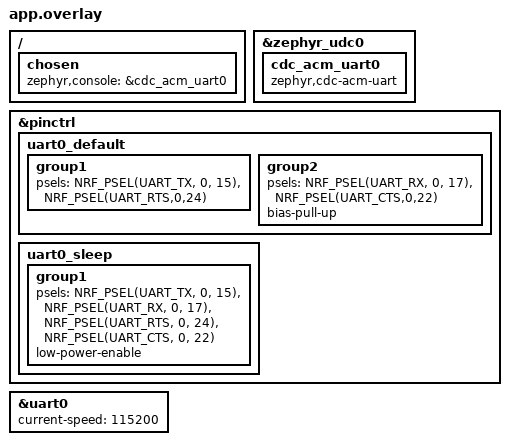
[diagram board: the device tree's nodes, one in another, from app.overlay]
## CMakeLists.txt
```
# SPDX-License-Identifier: Apache-2.0

cmake_minimum_required(VERSION 3.20.0)

find_package(Zephyr REQUIRED HINTS $ENV{ZEPHYR_BASE})
project(nRF52840_Pololu)

FILE(GLOB app_sources src/*.c)
target_sources(app PRIVATE ${app_sources})
```

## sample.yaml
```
sample:
  description: nRF52840 project for mimicing nRF52840 as an crazyflie
  name: nRF52840_Pololu
```

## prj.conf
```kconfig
CONFIG_CONSOLE=y
CONFIG_LOG=y
CONFIG_STDOUT_CONSOLE=y

# Use UART for Console
CONFIG_SERIAL=y
# CONFIG_UART_CONSOLE=y

# Use Segger RTT Console
#CONFIG_RTT_CONSOLE=y
#CONFIG_USE_SEGGER_RTT=y

# USB CDC Console Options:
# If using USB-CDC ensure app.overlay is present
CONFIG_USB_DEVICE_STACK=y
CONFIG_USB_DEVICE_PRODUCT="Zephyr Console"
CONFIG_UART_LINE_CTRL=y
CONFIG_USB_CDC_ACM=y
# Values below are for testing and MUST be configured for USB products
CONFIG_USB_DEVICE_VID=0x2FE3
CONFIG_USB_DEVICE_PID=0x100

CONFIG_NCS_SAMPLES_DEFAULTS=y
CONFIG_ESB=y

CONFIG_SYS_CLOCK_TICKS_PER_SEC=1000

CONFIG_CBPRINTF_FP_SUPPORT=y
```

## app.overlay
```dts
/*
 * Copyright (c) 2021 Nordic Semiconductor ASA
 *
 * SPDX-License-Identifier: Apache-2.0
 */


/ {
    chosen {
        zephyr,console = &cdc_acm_uart0;
    };
};

&zephyr_udc0 {
    cdc_acm_uart0: cdc_acm_uart0 {
        compatible = "zephyr,cdc-acm-uart";
    };
};

&pinctrl {
    uart0_default: uart0_default {
        group1 {
            psels = <NRF_PSEL(UART_TX, 0, 15)>,
                    <NRF_PSEL(UART_RTS,0,24)>;
        };
        group2 {
            psels = <NRF_PSEL(UART_RX, 0, 17)>,
                    <NRF_PSEL(UART_CTS,0,22)>;
            bias-pull-up;
        };
    };

	uart0_sleep: uart0_sleep {
		group1 {
			psels = <NRF_PSEL(UART_TX, 0, 15)>,
				<NRF_PSEL(UART_RX, 0, 17)>,
				<NRF_PSEL(UART_RTS, 0, 24)>,
				<NRF_PSEL(UART_CTS, 0, 22)>;
			low-power-enable;
		};
	};
};

&uart0 {
    current-speed = <115200>;
};
```

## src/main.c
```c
/*
 * Async ESB PRX with CRTP Handshake + Log Timer + param TOC/read/write
 * Author: Jiaming Li/Charlotte Stentzler
 * (Zephyr + nRF52840, Async Queue Version)
 */

#include <zephyr/device.h>
#include <zephyr/devicetree.h>
#include <zephyr/drivers/clock_control.h>
#include <zephyr/drivers/clock_control/nrf_clock_control.h>
#include <zephyr/drivers/gpio.h>
#include <zephyr/logging/log.h>
#include <zephyr/kernel.h>
#include <zephyr/types.h>
#include <nrf.h>
#include <esb.h>

#include "uart.h"
#include "led.h"
#include "robot_state.h"
#include "crtp.h"
#include "nrf_esb.h"
#include "crtp_param.h"
#include "crtp_log.h"


LOG_MODULE_REGISTER(esb_prx, CONFIG_ESB_PRX_APP_LOG_LEVEL);


K_THREAD_DEFINE(rx_thread_id, 2048, rx_worker, NULL, NULL, NULL, 3, 0, 0);

K_THREAD_DEFINE(tx_thread_id, 1024, tx_worker, NULL, NULL, NULL, 5, 0, 0);

K_THREAD_DEFINE(log_thread_id, 1024, log_task, NULL, NULL, NULL, 6, 0, 0);

K_THREAD_DEFINE(decode_thread_id, 1024, decode_worker, NULL, NULL, NULL, 7, 0, 0);

/* ============================ SYSTEM INIT ============================ */
int clocks_start(void)
{
    int err, res;
    struct onoff_manager *mgr;
    struct onoff_client cli;
    mgr = z_nrf_clock_control_get_onoff(CLOCK_CONTROL_NRF_SUBSYS_HF);
    if (!mgr) return -ENXIO;
    sys_notify_init_spinwait(&cli.notify);
    err = onoff_request(mgr, &cli);
    do { err = sys_notify_fetch_result(&cli.notify, &res); } while (err);
    return 0;
}

/* ============================ MAIN ============================ */
int main(void)
{
    /* BOOT MARKER - should appear immediately */
    LOG_INF("========================================");
    LOG_INF("=== nRF52840_Pololu Firmware v1.0 ===");
    LOG_INF("========================================");
    
    LOG_INF("Async ESB PRX Start");
    clocks_start();
    esb_initialize();
    esb_start_rx();
    log_blocks_init();
    uart_initialization();
    leds_init();

    LOG_INF("Ready for Crazyflie handshake + log streaming + param read/write");
    LOG_INF("========================================");
    LOG_INF("Missing components: robot status handling");
    LOG_INF("running basic tests ...");

    // Test: Send a parameter to robot on startup to verify UART TX
    k_msleep(1000);
    send_test_param_to_robot();

    uint32_t last_heartbeat = 0;
    uint32_t last_log_print = 0;
    uint32_t rx_count = 0;
    bool param_sync_reported = false;

    struct esb_payload cmd;
    while (1) {
        if (uart_queue_receive(&cmd) == 0) {
            rx_count++;
            if (is_parameter_packet(cmd.data, cmd.length)) {
                handle_parameter_packet(cmd.data, cmd.length);
                LOG_INF(">>> Param updated from ROBOT <<<");
                print_all_parameters();
            } else {
                // Forward other packets to radio
                esb_send_async(&cmd);
            }
        }

        uint32_t now = k_uptime_get_32();

        // Print log table every 30s
        if (now - last_log_print > 30000) {
            print_log_table();
            last_log_print = now;
        }

        // Heartbeat every 5s with RX counter
        if (now - last_heartbeat > 5000) {
            LOG_INF("Heartbeat: RX=%d uptime=%ds", rx_count, now/1000);
            last_heartbeat = now;

            // Check param sync status periodically until complete
            if (!param_sync_reported) {
                if (check_param_sync_status()) {
                    param_sync_reported = true;
                }
            }
        }

        k_msleep(50);
    }
}
```

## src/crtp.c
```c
#include "crtp.h"

/* Use the logging module registered in main.c */
LOG_MODULE_DECLARE(esb_prx);

uint8_t my_downlink_ctr = 0;

/* ============================ CRTP HANDLERS ============================ */
/* SCAN */
bool handle_scan_packet(const uint8_t *data, uint8_t len, uint8_t pipe)
{
    if (len == 3 && data[0] == 0xFF && data[1] == 0x05 && data[2] == 0x01)
    {
        struct esb_payload tx = {0};
        tx.pipe = pipe;
        tx.length = 3;
        memcpy(tx.data, data, 3);
        esb_send_async(&tx);
        LOG_INF("SCAN packet reply");
        return true;
    }
    return false;
}

/* KEEPALIVE */
bool handle_keepalive(const uint8_t *data, uint8_t len, uint8_t pipe)
{
    if (len == 1 && (data[0] & 0xF3) == 0xF3)
    {
        struct esb_payload tx = {0};
        tx.pipe = pipe;
        tx.length = 2;
        tx.data[0] = (0xAA & 0xF3) | (data[0] & 0x08) | (my_downlink_ctr << 2);
        tx.data[1] = 0x55;
        esb_send_async(&tx);
        my_downlink_ctr ^= 1;
        return true;
    }
    return false;
}

/* ========================== TX WORKER ========================== */
void tx_worker(void)
{
    struct esb_payload tx;

    while (1)
    {
        if (k_msgq_get(&tx_queue, &tx, K_FOREVER) == 0)
        {
            int ret;
            do
            {
                ret = esb_write_payload(&tx);
                if (ret != 0)
                {
                    k_msleep(1);
                }
            } while (ret != 0);
        }
    }
}

/* ========================== RX THREAD ========================== */
void rx_worker(void)
{
    struct esb_payload rx;
    while (1)
    {
        if (k_msgq_get(&rx_queue, &rx, K_FOREVER) == 0)
        {
            handle_received_packet(&rx);
        }
    }
}

void handle_received_packet(struct esb_payload *rx)
{
    uint8_t *data = rx->data;
    uint8_t len = rx->length;
    uint8_t pipe = rx->pipe;

    if (handle_scan_packet(data, len, pipe))
        return;
    if (handle_keepalive(data, len, pipe))
        return;

    uint8_t hdr = data[0] & 0xF3;
    uint8_t chan = (hdr & 0x0F);
    uint8_t port = ((hdr >> 4) & 0x0F);
    const uint8_t *pl = &data[1];
    uint8_t plen = len - 1;

    bool handled = false;

    handled |= handle_platform_crtp(port, chan, pl, plen, hdr, pipe);
    handled |= handle_param_crtp(port, chan, pl, plen, hdr, pipe);
    handled |= handle_memory_crtp(port, chan, pl, plen, hdr, pipe);
    handled |= handle_log_crtp(port, chan, pl, plen, hdr, pipe);

    if (!handled)
    {
        print_uart_payload(rx->data, rx->length);
        // LOG_INF("Forward non-CRTP packet to UART, len=%d %d %d", rx->data[0], rx->data[1], rx->data[2]);
    }
}
```

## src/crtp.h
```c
#pragma once
#ifndef CRTP_H
#define CRTP_H

#include <zephyr/device.h>
#include <zephyr/devicetree.h>
#include <zephyr/drivers/clock_control.h>
#include <zephyr/drivers/clock_control/nrf_clock_control.h>
#include <zephyr/drivers/gpio.h>
#include <zephyr/logging/log.h>
#include <zephyr/kernel.h>
#include <zephyr/types.h>
#include <nrf.h>
#include <esb.h>

#include "uart.h"
#include "robot_state.h"
#include "crtp_log.h"
#include "crtp_param.h"
#include "crtp_memory.h"
#include "crtp_platform.h"

extern uint8_t my_downlink_ctr;

/* Note: do NOT declare the log module in headers — declare per .c file */

extern struct k_msgq tx_queue;
extern struct k_msgq rx_queue;

/* ============================ CRTP HANDLERS ============================ */
bool handle_scan_packet(const uint8_t *data, uint8_t len, uint8_t pipe);
bool handle_keepalive(const uint8_t *data, uint8_t len, uint8_t pipe);

void tx_worker(void);
void rx_worker(void);
void handle_received_packet(struct esb_payload *rx);

#endif
```

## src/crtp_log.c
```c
#include "crtp_log.h"

/* Use the logging module registered in main.c */
LOG_MODULE_DECLARE(esb_prx);

/* Define the log blocks storage (single definition for the extern in header) */
log_block_t log_blocks[LOG_BLOCK_ID_MAX];

/* Access the new robot_log state */
extern log_snapshot_t robot_log;
extern struct k_mutex robot_log_lock;

/* ========================== LOG BLOCK HANDLING ========================== */
void log_blocks_init(void)
{
    for (int i = 0; i < LOG_BLOCK_ID_MAX; i++) {
        log_blocks[i].active = false;
        log_blocks[i].block_id = i;
        log_blocks[i].period_ms = 0;
        memset(log_blocks[i].vars, 0, sizeof(log_blocks[i].vars));
    }
}

/* ========================== LOG THREAD ========================== */
void log_task(void)
{
    uint32_t last_sent[LOG_BLOCK_ID_MAX] = {0};

    while (1) {
        uint32_t now = k_uptime_get_32();

        for (int i = 0; i < LOG_BLOCK_ID_MAX; i++) {
            if (!log_blocks[i].active)
                continue;

            if (now - last_sent[i] < (log_blocks[i].period_ms * 10))
                continue;

            last_sent[i] = now;

            // Read current log snapshot under mutex
            log_snapshot_t log;
            k_mutex_lock(&robot_log_lock, K_FOREVER);
            log = robot_log;
            k_mutex_unlock(&robot_log_lock);

            uint32_t ts = now & 0xFFFFFF;

            struct esb_payload tx = {0};
            tx.pipe = 0;
            tx.length = 1 + 3 + 1 + 6 * sizeof(float);
            tx.data[0] = (5 << 4) | 2 | (my_downlink_ctr << 2);
            tx.data[1] = log_blocks[i].block_id;
            memcpy(&tx.data[2], &ts, 3);

            if (log_blocks[i].block_id == 0) {
                // Block 0: position + velocity (x, y, yaw, x_des, y_des, yaw_des)
                memcpy(&tx.data[5], &log.x, 4);
                memcpy(&tx.data[9], &log.y, 4);
                memcpy(&tx.data[13], &log.yaw, 4);
                memcpy(&tx.data[17], &log.x_des, 4);
                memcpy(&tx.data[21], &log.y_des, 4);
                memcpy(&tx.data[25], &log.yaw_des, 4);
            }
            else if (log_blocks[i].block_id == 1) {
                // Block 1: errors + feedforward (x_err, y_err, yaw_err, v_ff, w_ff, 0)
                float zero = 0.0f;
                memcpy(&tx.data[5], &log.x_err, 4);
                memcpy(&tx.data[9], &log.y_err, 4);
                memcpy(&tx.data[13], &log.yaw_err, 4);
                memcpy(&tx.data[17], &log.v_ff, 4);
                memcpy(&tx.data[21], &log.w_ff, 4);
                memcpy(&tx.data[25], &zero, 4);
            }
            else if (log_blocks[i].block_id == 2) {
                // Block 2: wheel data (duty_l, duty_r, omega_l_cmd, omega_r_cmd, omega_l_meas, omega_r_meas)
                memcpy(&tx.data[5], &log.duty_l, 4);
                memcpy(&tx.data[9], &log.duty_r, 4);
                memcpy(&tx.data[13], &log.omega_l_cmd, 4);
                memcpy(&tx.data[17], &log.omega_r_cmd, 4);
                memcpy(&tx.data[21], &log.omega_l_meas, 4);
                memcpy(&tx.data[25], &log.omega_r_meas, 4);
            }
            else if (log_blocks[i].block_id == 3) {
                // Block 3: status (robot_mode, robot_running, t_ms as float, 0, 0, 0)
                extern uint8_t robot_mode;
                extern uint8_t robot_running;
                float mode_f = (float)robot_mode;
                float running_f = (float)robot_running;
                float t_ms_f = (float)log.t_ms;
                float zero = 0.0f;
                memcpy(&tx.data[5], &mode_f, 4);
                memcpy(&tx.data[9], &running_f, 4);
                memcpy(&tx.data[13], &t_ms_f, 4);
                memcpy(&tx.data[17], &zero, 4);
                memcpy(&tx.data[21], &zero, 4);
                memcpy(&tx.data[25], &zero, 4);
            }
            else {
                continue;
            }

            esb_send_async(&tx);
            my_downlink_ctr ^= 1;
        }
        k_msleep(1);
    }
}

/* ========================== LOG COMMANDS ========================== */
bool handle_log_crtp(uint8_t port, uint8_t chan, const uint8_t *pl, uint8_t plen, uint8_t hdr, uint8_t pipe)
{
	if (port != 5) return false;

    struct esb_payload tx = {0};
    tx.pipe = pipe;

    // TOC_INFO 
    if (port == 5 && chan == 0 && plen >= 1 && pl[0] == 0x03) {
        tx.length = 4;
        tx.data[0] = (hdr & 0xF3) | (pl[0] & 0x08) | (my_downlink_ctr << 2);
        tx.data[1] = 0x03;
        tx.data[2] = 0x18;    // number of items
        tx.data[3] = 0x00;
        esb_send_async(&tx);
        LOG_INF("LOG TOC_INFO reply sent (DL ctr=%d)", my_downlink_ctr);
        my_downlink_ctr ^= 1;
        return true;
    }

	// LOG TOC_GET_ITEM
	if (port == 5 && chan == 0 && plen >= 1 && pl[0] == 0x02) {
		uint16_t id = pl[1] | (pl[2] << 8);

		// Log variable groups matching the new block structure
		const char *group_pose = "pose";           // Block 0: position/setpoint
		const char *group_error = "error";         // Block 1: tracking errors
		const char *group_wheel = "wheel";         // Block 2: wheel/motor data
		const char *group_status = "status";       // Block 3: robot status
		const char *group = NULL;
		const char *name = NULL;

		switch (id) {
			// Block 0: pose (x, y, yaw, x_des, y_des, yaw_des)
			case 0: name = "x"; group = group_pose; break;
			case 1: name = "y"; group = group_pose; break;
			case 2: name = "yaw"; group = group_pose; break;
			case 3: name = "x_des"; group = group_pose; break;
			case 4: name = "y_des"; group = group_pose; break;
			case 5: name = "yaw_des"; group = group_pose; break;

			// Block 1: error (x_err, y_err, yaw_err, v_ff, w_ff, reserved)
			case 6: name = "x_err"; group = group_error; break;
			case 7: name = "y_err"; group = group_error; break;
			case 8: name = "yaw_err"; group = group_error; break;
			case 9: name = "v_ff"; group = group_error; break;
			case 10: name = "w_ff"; group = group_error; break;
			case 11: name = "reserved"; group = group_error; break;

			// Block 2: wheel (duty_l, duty_r, omega_l_cmd, omega_r_cmd, omega_l_meas, omega_r_meas)
			case 12: name = "duty_l"; group = group_wheel; break;
			case 13: name = "duty_r"; group = group_wheel; break;
			case 14: name = "omega_l_cmd"; group = group_wheel; break;
			case 15: name = "omega_r_cmd"; group = group_wheel; break;
			case 16: name = "omega_l_meas"; group = group_wheel; break;
			case 17: name = "omega_r_meas"; group = group_wheel; break;

			// Block 3: status (mode, running, t_ms, reserved...)
			case 18: name = "mode"; group = group_status; break;
			case 19: name = "running"; group = group_status; break;
			case 20: name = "t_ms"; group = group_status; break;
			case 21: name = "rsv1"; group = group_status; break;
			case 22: name = "rsv2"; group = group_status; break;
			case 23: name = "rsv3"; group = group_status; break;

			default: return true;
		}

		struct esb_payload tx = {0};
		tx.pipe = pipe;
		uint8_t *p = tx.data;

		// header
		p[0] = (hdr & 0xF3) | (pl[0] & 0x08) | (my_downlink_ctr << 2);
		// TOC_GET_ITEM echo
		p[1] = pl[0];
		// id
		p[2] = id & 0xFF;
		p[3] = id >> 8;

		p[4] = 0x07;   // type = float

		size_t offset = 5;
		size_t gl = strlen(group) + 1;
		memcpy(&p[offset], group, gl);
		offset += gl;
		size_t nl = strlen(name) + 1;
		memcpy(&p[offset], name, nl);
		offset += nl;

		tx.length = offset;
		esb_send_async(&tx);

		LOG_INF("LOG TOC_GET_ITEM reply id=%d (%s.%s)", id, group, name);
		my_downlink_ctr ^= 1;
		return true;
	}

	// CREATE BLOCK
    if (port == 5 && chan == 1 && plen >= 1 && pl[0] == 0x06) {
        struct esb_payload tx = {0};
		tx.length = 4;
					
		tx.data[0] = (hdr & 0xF3) | (pl[0] & 0x08) | (my_downlink_ctr << 2);
		tx.data[1] = pl[0];  // command echo (RESET)
		tx.data[2] = pl[1];
		tx.data[3] = 0x00;
		tx.pipe = pipe;
		esb_send_async(&tx);

		LOG_INF("LOG CREATE BLOCK reply sent");
		my_downlink_ctr ^= 1;  // Flip to match the radio protocol

        return true;
    }

	// LOG TOC APPEND_BLOCK_V2
	if (port == 5 && chan == 1 && plen >= 4 && pl[0] == 0x07) {
		uint8_t block_id = pl[1];
		uint8_t var_type = pl[2];
		uint16_t var_id = pl[3] | (pl[4] << 8);
		LOG_INF("APPEND_BLOCK_V2: block=%d var_id=%d type=0x%02X", block_id, var_id, var_type);

		struct esb_payload tx = {0};
		tx.pipe = pipe;
		tx.length = 4;
		tx.data[0] = (hdr & 0xF3) | (pl[0] & 0x08) | (my_downlink_ctr << 2);
		tx.data[1] = 0x07;       // echo APPEND_BLOCK_V2
		tx.data[2] = block_id;   // same block_id
		tx.data[3] = 0x00;       // success code (0=OK)
		esb_send_async(&tx);

		LOG_INF("LOG APPEND_BLOCK_V2 reply sent (block=%d)", block_id);
		my_downlink_ctr ^= 1;
		return true;
	}

	// LOG START_BLOCK
	if (port == 5 && chan == 1 && plen >= 3 && pl[0] == 0x03) {
		uint8_t block_id = pl[1];
		uint8_t period = pl[2];
		LOG_INF("LOG START_BLOCK received: block_id=%d, period=%d", block_id, period*10);

		struct esb_payload tx = {0};
		tx.pipe = pipe;
		tx.length = 4;
		tx.data[0] = (hdr & 0xF3) | (pl[0] & 0x08) | (my_downlink_ctr << 2);
		tx.data[1] = pl[0];     // echo START_BLOCK
		tx.data[2] = block_id; // same block_id
		tx.data[3] = 0x00;     // success code (0)
		esb_send_async(&tx);
		LOG_INF("LOG START_BLOCK reply sent");

        log_blocks[block_id].active = true;
        log_blocks[block_id].period_ms = period;
        LOG_INF("LOG START_BLOCK activated: block=%d, %dms", block_id, period*10);

		my_downlink_ctr ^= 1;
		return true;
	}

	// STOP_BLOCK (0x04)
	if (port == 5 && chan == 1 && plen >= 2 && pl[0] == 0x04) {
		uint8_t block_id = pl[1];
        log_blocks[block_id].active = false;

		struct esb_payload tx = {0};
		tx.length = 4;
		tx.data[0] = (hdr & 0xF3) | (pl[0] & 0x08) | (my_downlink_ctr << 2);
		tx.data[1] = pl[0];
		tx.data[2] = block_id;
		tx.data[3] = 0x00;
		tx.pipe = pipe;
		esb_send_async(&tx);

		LOG_INF("LOG STOP_BLOCK reply sent (block=%d)", block_id);
		my_downlink_ctr ^= 1;
		return true;
	}

    // RESET
    if (port == 5 && chan == 1 && plen >= 1 && pl[0] == 0x05) {
        struct esb_payload tx = {0};
		tx.length = 4;
					
		tx.data[0] = (hdr & 0xF3) | (pl[0] & 0x08) | (my_downlink_ctr << 2);
		tx.data[1] = 0x05;  // command echo (RESET)
		tx.data[2] = 0x00;
		tx.data[3] = 0x00;
		tx.pipe = pipe;
		esb_send_async(&tx);
		LOG_INF("LOG RESET reply sent");
		my_downlink_ctr ^= 1;  // Flip to match the radio protocol

        return true;
    }

    return false;
}

// Print current log snapshot values (for debugging)
void print_log_table(void)
{
    log_snapshot_t log;
    k_mutex_lock(&robot_log_lock, K_FOREVER);
    log = robot_log;
    k_mutex_unlock(&robot_log_lock);

    LOG_INF("=== Log Table (t=%u ms) ===", log.t_ms);
    LOG_INF("  pose: x=%.3f y=%.3f yaw=%.3f", (double)log.x, (double)log.y, (double)log.yaw);
    LOG_INF("  des:  x=%.3f y=%.3f yaw=%.3f", (double)log.x_des, (double)log.y_des, (double)log.yaw_des);
    LOG_INF("  err:  x=%.3f y=%.3f yaw=%.3f", (double)log.x_err, (double)log.y_err, (double)log.yaw_err);
    LOG_INF("  ff:   v=%.3f w=%.3f", (double)log.v_ff, (double)log.w_ff);
    LOG_INF("  wheel cmd: L=%.3f R=%.3f", (double)log.omega_l_cmd, (double)log.omega_r_cmd);
    LOG_INF("  wheel meas: L=%.3f R=%.3f", (double)log.omega_l_meas, (double)log.omega_r_meas);
    LOG_INF("  duty: L=%.3f R=%.3f", (double)log.duty_l, (double)log.duty_r);
}
```

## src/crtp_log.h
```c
#pragma once
#ifndef LOG_H
#define LOG_H

#include <zephyr/device.h>
#include <zephyr/devicetree.h>
#include <zephyr/drivers/clock_control.h>
#include <zephyr/drivers/clock_control/nrf_clock_control.h>
#include <zephyr/drivers/gpio.h>
#include <zephyr/logging/log.h>
#include <zephyr/kernel.h>
#include <zephyr/types.h>
#include <nrf.h>
#include <esb.h>

#include "crtp.h"
#include "nrf_esb.h"
#include "uart.h"
#include "robot_state.h"

#define LOG_BLOCK_ID_MAX 4

extern uint8_t my_downlink_ctr;

typedef struct {
    bool active;
    uint8_t block_id;
    uint32_t period_ms;
    float vars[3]; // roll pitch yaw
} log_block_t;

extern log_block_t log_blocks[LOG_BLOCK_ID_MAX];

void log_blocks_init(void);
void log_task(void);
bool handle_log_crtp(uint8_t port, uint8_t chan, const uint8_t *pl, uint8_t plen, uint8_t hdr, uint8_t pipe);
void print_log_table(void);

#endif
```

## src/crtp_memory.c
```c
#include "crtp_memory.h"

/* Use the logging module registered in main.c */
LOG_MODULE_DECLARE(esb_prx);

/* MEMORY */
bool handle_memory_crtp(uint8_t port, uint8_t chan, const uint8_t *pl,
                               uint8_t plen, uint8_t hdr, uint8_t pipe)
{
    if (port == 4 && chan == 0 && plen >= 1 && pl[0] == 0x01) {
        struct esb_payload tx = {0};
        tx.pipe = pipe;
        tx.length = 4;
        tx.data[0] = (hdr & 0xF3) | (pl[0] & 0x08) | (my_downlink_ctr << 2);
        tx.data[1] = 0x01;
        tx.data[2] = 0x00;
        tx.data[3] = 0x00;
        esb_send_async(&tx);
        LOG_INF("MEMORY reply");
        my_downlink_ctr ^= 1;
        return true;
    }
    return false;
}
```

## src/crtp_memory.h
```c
#pragma once
#ifndef CRTP_MEMORY_H
#define CRTP_MEMORY_H

#include <zephyr/device.h>
#include <zephyr/devicetree.h>
#include <zephyr/drivers/clock_control.h>
#include <zephyr/drivers/clock_control/nrf_clock_control.h>
#include <zephyr/drivers/gpio.h>
#include <zephyr/logging/log.h>
#include <zephyr/kernel.h>
#include <zephyr/types.h>
#include <nrf.h>
#include <esb.h>

#include "crtp.h"
#include "uart.h"
#include "nrf_esb.h"

extern uint8_t my_downlink_ctr;

bool handle_memory_crtp(uint8_t port, uint8_t chan, const uint8_t *pl, uint8_t plen, uint8_t hdr, uint8_t pipe);

#endif
```

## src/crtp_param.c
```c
// Definitions for parameters declared in param.h
#include "crtp_param.h"

/* Use the logging module registered in main.c */
LOG_MODULE_DECLARE(esb_prx);

// Some Robot Params --> dummies for pololu
float kp_inner = 0.0f;
float ki_inner = 0.1f;
uint8_t kd_inner = 0;

// Trajectory gains
float kx_traj = 10.0f;
float ky_traj = 10.0f;
float ktheta_traj = 5.0f;

// Robot parameters - extended set to match Rust RobotConfig
uint8_t robot_id = 7;
float joystick_control_dt_ms = 50.0f;
float traj_following_dt_s = 0.05f;
float wheel_radius = 0.016f;
float wheel_base = 0.085f;
float motor_direction_left = -1.0f;
float motor_direction_right = 1.0f;
float motor_max_duty_left = 1.0f;
float motor_max_duty_right = 1.0f;
float k_clip = 1.0f;
float gear_ratio = 100.37f;
float encoder_cpr = -1204.44f;
float max_speed = 0.5f;
float max_omega = 3.14f;
float wheel_max = 31.25f;

// Status parameters (read-only, received from robot)
uint8_t robot_mode = 0;      // 0=Menu, 1=TeleOp, 2=TrajMocap, 3=TrajDuty
uint8_t robot_running = 0;   // 0=idle, 1=running

// Parameter sync statistics
uint32_t param_packets_received = 0;
uint32_t param_packets_valid = 0;
uint32_t param_packets_invalid = 0;

// Tracks which config parameters (0-20) have been received from robot
uint32_t param_received_mask = 0;


// param handling
bool handle_param_crtp(uint8_t port, uint8_t chan, const uint8_t *pl, uint8_t plen, uint8_t hdr, uint8_t pipe)
{
    if (port != 2)
        return false;

    struct esb_payload tx = {0};
    tx.pipe = pipe;

    // TOC_INFO (chan 0, cmd 0x03)
    if (chan == 0 && plen >= 1 && pl[0] == 0x03)
    {
        uint32_t crc = param_calculate_crc();
        tx.length = 8;
        tx.data[0] = (hdr & 0xF3) | (pl[0] & 0x08) | (my_downlink_ctr << 2);
        tx.data[1] = 0x03;                      // TOC_INFO echo
        tx.data[2] = PARAM_COUNT & 0xFF;        // count low byte
        tx.data[3] = (PARAM_COUNT >> 8) & 0xFF; // count high byte
        memcpy(&tx.data[4], &crc, 4);           // CRC (little-endian)
        esb_send_async(&tx);
        LOG_INF("PARAM TOC_INFO reply: count=%d crc=0x%08X", PARAM_COUNT, crc);
        my_downlink_ctr ^= 1;
        return true;
    }

    // TOC_ELEMENT (chan 0, cmd 0x02)
    if (chan == 0 && plen >= 3 && pl[0] == 0x02)
    {
        uint16_t id = pl[1] | (pl[2] << 8);

        if (id >= PARAM_COUNT)
        {
            LOG_WRN("PARAM TOC_ELEMENT: id=%d out of range", id);
            return true;
        }

        const param_t *p = &param_toc[id];

        // Build type byte: lower 4 bits = type, bit 6 = writable (0=writable, 1=readonly)
        uint8_t type_byte = p->type;
        if (p->access == PARAM_RONLY)
        {
            type_byte |= (1 << 6); // Set readonly bit
        }

        uint8_t *out = tx.data;
        out[0] = (hdr & 0xF3) | (pl[0] & 0x08) | (my_downlink_ctr << 2);
        out[1] = 0x02;      // TOC_ELEMENT echo
        out[2] = id & 0xFF; // id low byte
        out[3] = id >> 8;   // id high byte
        out[4] = type_byte; // type + access flags

        size_t offset = 5;
        size_t gl = strlen(p->group) + 1;
        size_t nl = strlen(p->name) + 1;
        memcpy(&out[offset], p->group, gl);
        offset += gl;
        memcpy(&out[offset], p->name, nl);
        offset += nl;

        tx.length = offset;
        esb_send_async(&tx);
        LOG_INF("PARAM TOC_ELEMENT: id=%d %s.%s type=0x%02X", id, p->group, p->name, type_byte);
        my_downlink_ctr ^= 1;
        return true;
    }

    // READ (chan 1)
    if (chan == 1 && plen >= 2)
    {
        uint16_t id = pl[0] | (pl[1] << 8);

        if (id >= PARAM_COUNT)
        {
            LOG_WRN("PARAM READ: id=%d out of range", id);
            return true;
        }

        const param_t *p = &param_toc[id];
        uint8_t size = param_get_size(p->type);

        tx.data[0] = (hdr & 0xF3) | (my_downlink_ctr << 2);
        tx.data[1] = id & 0xFF;
        tx.data[2] = id >> 8;
        tx.data[3] = 0x00; // Success code

        // Copy value in little-endian format
        memcpy(&tx.data[4], p->address, size);
        tx.length = 4 + size;

        esb_send_async(&tx);
        LOG_INF("PARAM READ: id=%d %s.%s", id, p->group, p->name);
        my_downlink_ctr ^= 1;
        return true;
    }

    // WRITE (chan 2)
    if (chan == 2 && plen >= 3)
    {
        uint16_t id = pl[0] | (pl[1] << 8);

        if (id >= PARAM_COUNT)
        {
            LOG_WRN("PARAM WRITE: id=%d out of range", id);
            return true;
        }

        const param_t *p = &param_toc[id];

        // Check if writable
        if (p->access == PARAM_RONLY)
        {
            LOG_WRN("PARAM WRITE: id=%d is read-only", id);
            // Still echo back but don't write
            tx.data[0] = (hdr & 0xF3) | (my_downlink_ctr << 2);
            tx.data[1] = id & 0xFF;
            tx.data[2] = id >> 8;
            tx.data[3] = 0x01; // Error code: read-only
            tx.length = 4;
            esb_send_async(&tx);
            my_downlink_ctr ^= 1;
            return true;
        }

        uint8_t size = param_get_size(p->type);

        // Verify we have enough data
        if (plen < 2 + size)
        {
            LOG_WRN("PARAM WRITE: insufficient data");
            return true;
        }

        // Write the value to local cache
        memcpy(p->address, &pl[2], size);

        // Forward parameter to robot via UART
        // Format: [length=8][header=0x3C][param_id][value(4 bytes f32)][checksum(2 bytes)]
        float value_f32;
        if (p->type == PARAM_TYPE_UINT8) {
            value_f32 = (float)(*(uint8_t *)p->address);
        } else {
            value_f32 = *(float *)p->address;
        }

        parameter_packet_t uart_pkt;
        uart_pkt.length = 8;  // length excluding length byte itself
        uart_pkt.header = 0x3C;
        uart_pkt.param_id = (uint8_t)id;
        uart_pkt.value = value_f32;
        uart_pkt.checksum = param_packet_checksum(&uart_pkt);

        // Send parameter to robot via UART
        print_uart_payload((uint8_t *)&uart_pkt, sizeof(uart_pkt));
        LOG_INF("PARAM WRITE: id=%d %s.%s -> UART (value=%.3f, checksum=0x%04X)", 
                id, p->group, p->name, (double)value_f32, uart_pkt.checksum);

        // Echo back the written value to radio
        tx.data[0] = (hdr & 0xF3) | (my_downlink_ctr << 2);
        tx.data[1] = id & 0xFF;
        tx.data[2] = id >> 8;
        memcpy(&tx.data[3], &pl[2], size);
        tx.length = 3 + size;

        esb_send_async(&tx);
        my_downlink_ctr ^= 1;

        // Print param table after client update
        LOG_INF(">>> Param updated from CLIENT <<<");
        print_all_parameters();
        return true;
    }

    return false;
}

// crc32 for TOC
uint32_t param_calculate_crc(void)
{
    uint32_t crc = 0;
    for (int i = 0; i < PARAM_COUNT; i++)
    {
        const param_t *p = &param_toc[i];
        // Simple hash of group and name
        const char *s = p->group;
        while (*s)
            crc = crc * 31 + *s++;
        s = p->name;
        while (*s)
            crc = crc * 31 + *s++;
        crc += p->type;
    }
    return crc;
}

// get parameters size
uint8_t param_get_size(uint8_t type)
{
    switch (type)
    {
    case PARAM_TYPE_UINT8:
    case PARAM_TYPE_INT8:
        return 1;
    case PARAM_TYPE_UINT16:
    case PARAM_TYPE_INT16:
        return 2;
    case PARAM_TYPE_UINT32:
    case PARAM_TYPE_INT32:
    case PARAM_TYPE_FLOAT:
        return 4;
    default:
        return 0;
    }
}

// Calculate checksum for parameter packet (matches Rust implementation)
uint16_t param_packet_checksum(const parameter_packet_t *packet)
{
    const uint8_t *value_bytes = (const uint8_t *)&packet->value;
    uint16_t sum = packet->length + packet->header + packet->param_id +
                   value_bytes[0] + value_bytes[1] + value_bytes[2] + value_bytes[3];
    return sum;
}

// Parse and handle parameter packet from UART (received from robot)
// Format: [length=8][0x3C][param_id][value(4)][checksum(2)] = 9 bytes total
bool handle_parameter_packet(const uint8_t *data, uint8_t len)
{
    param_packets_received++;

    // Expect exactly 9 bytes: length(1) + header(1) + id(1) + value(4) + checksum(2)
    if (len != sizeof(parameter_packet_t))
    {
        LOG_WRN("Invalid parameter packet length: %d (expected %d)", len, sizeof(parameter_packet_t));
        param_packets_invalid++;
        return false;
    }

    parameter_packet_t packet;
    memcpy(&packet, data, sizeof(parameter_packet_t));

    // Verify length field
    if (packet.length != 8)
    {
        LOG_WRN("Invalid parameter packet length field: %d (expected 8)", packet.length);
        param_packets_invalid++;
        return false;
    }

    // Verify checksum
    uint16_t expected_checksum = param_packet_checksum(&packet);
    if (packet.checksum != expected_checksum)
    {
        LOG_WRN("Parameter packet checksum mismatch: got 0x%04X, expected 0x%04X",
                packet.checksum, expected_checksum);
        param_packets_invalid++;
        return false;
    }

    // Verify header
    if (packet.header != 0x3C)
    {
        LOG_WRN("Invalid parameter packet header: 0x%02X", packet.header);
        param_packets_invalid++;
        return false;
    }

    // Update parameter if valid ID
    if (packet.param_id >= PARAM_COUNT)
    {
        LOG_WRN("Parameter ID out of range: %d", packet.param_id);
        param_packets_invalid++;
        return false;
    }

    const param_t *p = &param_toc[packet.param_id];

    // Special handling for uint8_t parameters stored as float
    if (packet.param_id == 0)
    {
        robot_id = (uint8_t)packet.value;
        LOG_INF("PARAM SYNC: %s.%s = %d (uint8)", p->group, p->name, robot_id);
    }
    else if (packet.param_id == 12)
    {
        kd_inner = (uint8_t)packet.value;
        LOG_INF("PARAM SYNC: %s.%s = %d (uint8)", p->group, p->name, kd_inner);
    }
    // Status parameters (21=mode, 22=running) - read-only, received from robot
    else if (packet.param_id == 21)
    {
        robot_mode = (uint8_t)packet.value;
        LOG_INF("PARAM SYNC: %s.%s = %d (mode)", p->group, p->name, robot_mode);
    }
    else if (packet.param_id == 22)
    {
        robot_running = (uint8_t)packet.value;
        LOG_INF("PARAM SYNC: %s.%s = %d (running)", p->group, p->name, robot_running);
    }
    // All other parameters are floats
    else
    {
        *(float *)p->address = packet.value;
        LOG_INF("PARAM SYNC: %s.%s = %.6f", p->group, p->name, packet.value);
    }

    // Mark this parameter as received in the bitmask
    if (packet.param_id < 32)
    {
        param_received_mask |= (1u << packet.param_id);
    }

    param_packets_valid++;
    return true;
}

// Check if received UART data is a parameter packet
// Format: [length=8][header=0x3C][...] = 9 bytes total
bool is_parameter_packet(const uint8_t *data, uint8_t len)
{
    return (len == sizeof(parameter_packet_t) && data[0] == 8 && data[1] == 0x3C);
}

// Print all current parameter values (for debugging)
void print_all_parameters(void)
{
    LOG_INF("=== Parameter Status ===");
    LOG_INF("Packets: received=%u valid=%u invalid=%u",
            param_packets_received, param_packets_valid, param_packets_invalid);
    LOG_INF("=== Current Parameter Values ===");
    for (int i = 0; i < PARAM_COUNT; i++)
    {
        const param_t *p = &param_toc[i];
        if (i == 0)
        {
            LOG_INF("%2d: %s.%s = %d", i, p->group, p->name, robot_id);
        }
        else if (i == 12)
        {
            LOG_INF("%2d: %s.%s = %d", i, p->group, p->name, kd_inner);
        }
        else if (i == 21)
        {
            LOG_INF("%2d: %s.%s = %d (mode)", i, p->group, p->name, robot_mode);
        }
        else if (i == 22)
        {
            LOG_INF("%2d: %s.%s = %d (running)", i, p->group, p->name, robot_running);
        }
        else
        {
            LOG_INF("%2d: %s.%s = %.6f", i, p->group, p->name, *(float *)p->address);
        }
    }
    LOG_INF("=== End Parameter Values ===");
}

// Send a test parameter packet to robot via UART (for debugging)
// Sends param_id=10 (KP_INNER) with value=1.234
void send_test_param_to_robot(void)
{
    LOG_INF("=== UART TX TEST START ===");
    
    parameter_packet_t test_pkt;
    test_pkt.length = 8;
    test_pkt.header = 0x3C;
    test_pkt.param_id = 10;  // KP_INNER
    test_pkt.value = 1.234f;
    test_pkt.checksum = param_packet_checksum(&test_pkt);

    uint8_t *bytes = (uint8_t *)&test_pkt;
    LOG_INF("Packet size: %d bytes", (int)sizeof(test_pkt));
    LOG_INF("TX bytes: %02X %02X %02X %02X %02X %02X %02X %02X %02X",
            bytes[0], bytes[1], bytes[2], bytes[3], bytes[4],
            bytes[5], bytes[6], bytes[7], bytes[8]);

    LOG_INF("Calling print_uart_payload()...");
    print_uart_payload((uint8_t *)&test_pkt, sizeof(test_pkt));
    LOG_INF("=== UART TX TEST DONE ===");
}

// Check and report parameter sync status from robot
// Returns true if all parameters (0-22) have been received
bool check_param_sync_status(void)
{
    // Expected mask: bits 0-22 all set = 0x7FFFFF (23 bits)
    uint32_t expected_mask = (1u << PARAM_CONFIG_COUNT) - 1;
    uint32_t received = param_received_mask & expected_mask;

    int received_count = 0;
    for (int i = 0; i < PARAM_CONFIG_COUNT; i++)
    {
        if (received & (1u << i))
        {
            received_count++;
        }
    }

    if (received == expected_mask)
    {
        LOG_INF("=== PARAM SYNC OK: All %d/%d parameters received from robot ===",
                received_count, PARAM_CONFIG_COUNT);
        LOG_INF("  Packets: total=%u valid=%u invalid=%u",
                param_packets_received, param_packets_valid, param_packets_invalid);
        return true;
    }
    else
    {
        LOG_WRN("=== PARAM SYNC INCOMPLETE: %d/%d parameters received ===",
                received_count, PARAM_CONFIG_COUNT);
        LOG_WRN("  Missing parameters:");
        for (int i = 0; i < PARAM_CONFIG_COUNT; i++)
        {
            if (!(received & (1u << i)))
            {
                const param_t *p = &param_toc[i];
                LOG_WRN("    ID %d: %s.%s", i, p->group, p->name);
            }
        }
        LOG_WRN("  Packets: total=%u valid=%u invalid=%u",
                param_packets_received, param_packets_valid, param_packets_invalid);
        return false;
    }
}
```

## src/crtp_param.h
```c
#pragma once
#ifndef CRTP_PARAM_H
#define CRTP_PARAM_H

#include <zephyr/device.h>
#include <zephyr/devicetree.h>
#include <zephyr/drivers/clock_control.h>
#include <zephyr/drivers/clock_control/nrf_clock_control.h>
#include <zephyr/drivers/gpio.h>
#include <zephyr/logging/log.h>
#include <zephyr/kernel.h>
#include <zephyr/types.h>
#include <nrf.h>
#include <esb.h>

#include "crtp.h"
#include "uart.h"
#include "nrf_esb.h"
#include "led.h"

extern uint8_t my_downlink_ctr;

/* ========================== PARAM Table ========================== */
// Parameter types
#define PARAM_TYPE_UINT8 0x00
#define PARAM_TYPE_INT8 0x01
#define PARAM_TYPE_UINT16 0x02
#define PARAM_TYPE_INT16 0x03
#define PARAM_TYPE_UINT32 0x04
#define PARAM_TYPE_INT32 0x05
#define PARAM_TYPE_FLOAT 0x06

// Parameter access
#define PARAM_RONLY 0x00
#define PARAM_RW 0x01

// Some Robot Params --> dummies for pololu
// Declarations only: actual definitions (with initializers) live in src/param.c
extern float kp_inner;
extern float ki_inner;
extern uint8_t kd_inner;

// Trajectory gains (declared here, defined in src/param.c)
extern float kx_traj;
extern float ky_traj;
extern float ktheta_traj;

// Robot parameters - extended set to match Rust RobotConfig
extern uint8_t robot_id;
extern float joystick_control_dt_ms;
extern float traj_following_dt_s;
extern float wheel_radius;
extern float wheel_base;
extern float motor_direction_left;
extern float motor_direction_right;
extern float motor_max_duty_left;
extern float motor_max_duty_right;
extern float k_clip;
extern float gear_ratio;
extern float encoder_cpr;
extern float max_speed;
extern float max_omega;
extern float wheel_max;

// Status parameters (read-only, received from robot)
// For orchestrator controlled by ROS node via controller interface
extern uint8_t robot_mode;    // 0=Menu, 1=TeleOp, 2=TrajMocap, 3=TrajDuty
extern uint8_t robot_running; // 0=idle, 1=running

// Parameter packet structure
// Must be packed to ensure exactly 9 bytes with no padding
// TODO: check again with crazyflie-lib ... unify with robot and dongle
#pragma pack(push, 1)
typedef struct
{
    uint8_t length;    // Byte 0: Packet length (8 = excluding length byte)
    uint8_t header;    // Byte 1: 0x3C (Parameter packet identifier)
    uint8_t param_id;  // Byte 2: Parameter ID (0-20)
    float value;       // Bytes 3-6: f32 Little-Endian
    uint16_t checksum; // Bytes 7-8: 16-bit checksum (LE)
} parameter_packet_t;
#pragma pack(pop)

// Parameter table entry
typedef struct
{
    uint8_t type;
    uint8_t access;
    const char *group;
    const char *name;
    void *address;
} param_t;

//=========================== PARAM Table ==========================/
// Parameter Table of Contents (matches Rust parameter IDs in robot firmware)
static const param_t param_toc[] = {
    {PARAM_TYPE_UINT8, PARAM_RW, "robot", "ROBOT_ID", &robot_id},                     // 0
    {PARAM_TYPE_FLOAT, PARAM_RW, "robot", "JOYSTICK_DT_MS", &joystick_control_dt_ms}, // 1
    {PARAM_TYPE_FLOAT, PARAM_RW, "robot", "TRAJ_DT_S", &traj_following_dt_s},         // 2
    {PARAM_TYPE_FLOAT, PARAM_RW, "robot", "WHEEL_RADIUS", &wheel_radius},             // 3
    {PARAM_TYPE_FLOAT, PARAM_RW, "robot", "WHEEL_BASE", &wheel_base},                 // 4
    {PARAM_TYPE_FLOAT, PARAM_RW, "robot", "MOTOR_DIR_L", &motor_direction_left},      // 5
    {PARAM_TYPE_FLOAT, PARAM_RW, "robot", "MOTOR_DIR_R", &motor_direction_right},     // 6
    {PARAM_TYPE_FLOAT, PARAM_RW, "robot", "MOTOR_MAX_L", &motor_max_duty_left},       // 7
    {PARAM_TYPE_FLOAT, PARAM_RW, "robot", "MOTOR_MAX_R", &motor_max_duty_right},      // 8
    {PARAM_TYPE_FLOAT, PARAM_RW, "robot", "K_CLIP", &k_clip},                         // 9
    {PARAM_TYPE_FLOAT, PARAM_RW, "robot", "KP_INNER", &kp_inner},                     // 10
    {PARAM_TYPE_FLOAT, PARAM_RW, "robot", "KI_INNER", &ki_inner},                     // 11
    {PARAM_TYPE_UINT8, PARAM_RW, "robot", "KD_INNER", &kd_inner},                     // 12
    {PARAM_TYPE_FLOAT, PARAM_RW, "robot", "KX_TRAJ", &kx_traj},                       // 13
    {PARAM_TYPE_FLOAT, PARAM_RW, "robot", "KY_TRAJ", &ky_traj},                       // 14
    {PARAM_TYPE_FLOAT, PARAM_RW, "robot", "KTHETA_TRAJ", &ktheta_traj},               // 15
    {PARAM_TYPE_FLOAT, PARAM_RW, "robot", "GEAR_RATIO", &gear_ratio},                 // 16
    {PARAM_TYPE_FLOAT, PARAM_RW, "robot", "ENCODER_CPR", &encoder_cpr},               // 17
    {PARAM_TYPE_FLOAT, PARAM_RW, "robot", "MAX_SPEED", &max_speed},                   // 18
    {PARAM_TYPE_FLOAT, PARAM_RW, "robot", "MAX_OMEGA", &max_omega},                   // 19
    {PARAM_TYPE_FLOAT, PARAM_RW, "robot", "WHEEL_MAX", &wheel_max},                   // 20
    // Status parameters (read-only, sent from robot to dongle)
    {PARAM_TYPE_UINT8, PARAM_RONLY, "status", "MODE", &robot_mode},       // 21
    {PARAM_TYPE_UINT8, PARAM_RONLY, "status", "RUNNING", &robot_running}, // 22
};

#define PARAM_COUNT (sizeof(param_toc) / sizeof(param_t))

bool handle_param_crtp(uint8_t port, uint8_t chan, const uint8_t *pl, uint8_t plen, uint8_t hdr, uint8_t pipe);

// crc32 for TOC
uint32_t param_calculate_crc(void);

// get parameters size
uint8_t param_get_size(uint8_t type);

/* ========================== PARAMETER SYNC ========================== */
// Parameter sync statistics
extern uint32_t param_packets_received;
extern uint32_t param_packets_valid;
extern uint32_t param_packets_invalid;

// Tracks which parameters (0-22) have been received from robot
// Bit i is set when param_id i has been received at least once
extern uint32_t param_received_mask;

// Number of parameters expected from robot at startup (IDs 0-22)
#define PARAM_CONFIG_COUNT 23

// Calculate checksum for parameter packet (matches robot firmware implementation)
uint16_t param_packet_checksum(const parameter_packet_t *packet);

// Parse and handle parameter packet from UART
bool handle_parameter_packet(const uint8_t *data, uint8_t len);

// Check if received UART data is a parameter packet
bool is_parameter_packet(const uint8_t *data, uint8_t len);

// Print all current parameter values (for debugging)
void print_all_parameters(void);

// Send a test parameter packet to robot via UART (for debugging)
void send_test_param_to_robot(void);

// Check and report parameter sync status from robot
// Returns true if all config parameters (0-20) have been received
bool check_param_sync_status(void);

#endif
```

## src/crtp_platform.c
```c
#include "crtp_platform.h"

/* Use the logging module registered in main.c */
LOG_MODULE_DECLARE(esb_prx);

/* PLATFORM */
bool handle_platform_crtp(uint8_t port, uint8_t chan, const uint8_t *pl,
                                 uint8_t plen, uint8_t hdr, uint8_t pipe)
{
    if (port == 13 && chan == 1 && plen >= 1 && pl[0] == 0x00) {
        struct esb_payload tx = {0};
        tx.pipe = pipe;
        tx.length = 3;
        tx.data[0] = (hdr & 0xF3) | (pl[0] & 0x08) | (my_downlink_ctr << 2);
        tx.data[1] = 0x00;
        tx.data[2] = 0x0A; // version
        esb_send_async(&tx);
        LOG_INF("PLATFORM reply sent");
        my_downlink_ctr ^= 1;
        return true;
    }
    return false;
}
```

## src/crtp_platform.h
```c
#pragma once
#ifndef CRTP_PLATFORM_H
#define CRTP_PLATFORM_H

#include <zephyr/device.h>
#include <zephyr/devicetree.h>
#include <zephyr/drivers/clock_control.h>
#include <zephyr/drivers/clock_control/nrf_clock_control.h>
#include <zephyr/drivers/gpio.h>
#include <zephyr/logging/log.h>
#include <zephyr/kernel.h>
#include <zephyr/types.h>
#include <nrf.h>
#include <esb.h>

#include "crtp.h"
#include "uart.h"
#include "nrf_esb.h"

extern uint8_t my_downlink_ctr;

bool handle_platform_crtp(uint8_t port, uint8_t chan, const uint8_t *pl, uint8_t plen, uint8_t hdr, uint8_t pipe);

#endif
```

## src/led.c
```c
#include "led.h"

/* Use the logging module registered in main.c */
LOG_MODULE_DECLARE(esb_prx);

int leds_init(void)
{
	if (!device_is_ready(leds[0].port)) {
		LOG_ERR("LEDs port not ready");
		return -ENODEV;
	}

	for (size_t i = 0; i < ARRAY_SIZE(leds); i++) {
		int err = gpio_pin_configure_dt(&leds[i], GPIO_OUTPUT);

		if (err) {
			LOG_ERR("Unable to configure LED%u, err %d.", i, err);
			return err;
		}
	}

	return 0;
}

void leds_update(uint8_t value)
{
	bool led0_status = !(value % 8 > 0 && value % 8 <= 4);
	bool led1_status = !(value % 8 > 1 && value % 8 <= 5);
	bool led2_status = !(value % 8 > 2 && value % 8 <= 6);
	bool led3_status = !(value % 8 > 3);

	gpio_port_pins_t mask = BIT(leds[0].pin) | BIT(leds[1].pin) |
				BIT(leds[2].pin) | BIT(leds[3].pin);

	gpio_port_value_t val = led0_status << leds[0].pin |
				led1_status << leds[1].pin |
				led2_status << leds[2].pin |
				led3_status << leds[3].pin;

	gpio_port_set_masked_raw(leds[0].port, mask, val);
}
```

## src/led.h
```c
#pragma once
#ifndef LED_H
#define LED_H

#include <zephyr/device.h>
#include <zephyr/devicetree.h>
#include <zephyr/drivers/clock_control.h>
#include <zephyr/drivers/clock_control/nrf_clock_control.h>
#include <zephyr/drivers/gpio.h>
#include <zephyr/logging/log.h>
#include <zephyr/kernel.h>
#include <zephyr/types.h>
#include <nrf.h>
#include <esb.h>

/* Note: do NOT declare the log module in headers — declare per .c file */

/* ====================== LED Initialization ====================== */
static const struct gpio_dt_spec leds[] = {
	GPIO_DT_SPEC_GET(DT_ALIAS(led0), gpios),
	GPIO_DT_SPEC_GET(DT_ALIAS(led1), gpios),
	GPIO_DT_SPEC_GET(DT_ALIAS(led2), gpios),
	GPIO_DT_SPEC_GET(DT_ALIAS(led3), gpios),
};

int leds_init(void);
void leds_update(uint8_t value);


#endif
```
